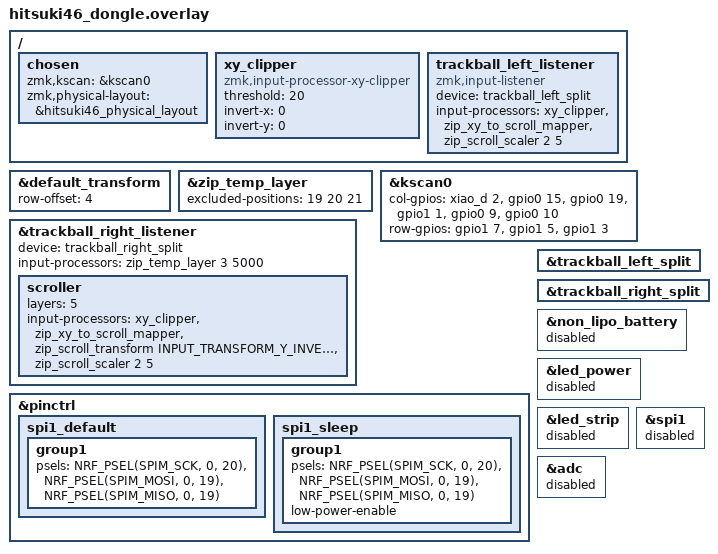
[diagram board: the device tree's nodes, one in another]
#include "hitsuki46.dtsi"
#include <dt-bindings/zmk/input_transform.h>
#include <dt-bindings/input/input-event-codes.h>
#include <input/processors.dtsi>
#include <dt-bindings/zmk/pointing.h>

//=============================================================================
// Trackball Mode Configuration on the Prospector central dongle
// 0 = CURSOR mode (mouse cursor movement)
// 1 = SCROLL mode (scroll operation)
//=============================================================================
#define LEFT_TRACKBALL_MODE  1
#define RIGHT_TRACKBALL_MODE 0
//=============================================================================

/ {
    chosen {
        zmk,kscan = &kscan0;
        zmk,physical-layout = &hitsuki46_physical_layout;
        /* The dongle has no local battery sensor (non_lipo_battery and adc are
         * disabled below). Drop the zmk,battery chosen inherited from the dtsi so
         * battery.c does not try to DEVICE_DT_GET a disabled device. Peripheral
         * battery levels are still fetched/reported via the split central. */
        /delete-property/ zmk,battery;
    };

    xy_clipper: xy_clipper {
        compatible = "zmk,input-processor-xy-clipper";
        #input-processor-cells = <0>;
        threshold = <20>;
        invert-x = <0>;
        invert-y = <0>;
    };

    // Left trackball input forwarded from the L peripheral.
    trackball_left_listener: trackball_left_listener {
        compatible = "zmk,input-listener";
        status = "okay";
        device = <&trackball_left_split>;

#if LEFT_TRACKBALL_MODE == 1
        input-processors =
            <&xy_clipper>,
            <&zip_xy_to_scroll_mapper>,
            <&zip_scroll_scaler 2 5>;
#else
        input-processors =
            <&zip_xy_transform INPUT_TRANSFORM_Y_INVERT>,
            <&zip_temp_layer 3 5000>;

        scroller {
            layers = <5>;
            input-processors =
                <&xy_clipper>,
                <&zip_xy_to_scroll_mapper>,
                <&zip_scroll_scaler 2 5>;
        };
#endif
    };
};

&default_transform {
    row-offset = <4>;
};

// Keep the auto mouse layer active only while pressing J/K/L.
&zip_temp_layer {
    excluded-positions = <19 20 21>;
};

// Right trackball input forwarded from the R peripheral.
&trackball_right_listener {
    status = "okay";
    device = <&trackball_right_split>;

#if RIGHT_TRACKBALL_MODE == 1
    input-processors =
        <&xy_clipper>,
        <&zip_xy_to_scroll_mapper>,
        <&zip_scroll_transform INPUT_TRANSFORM_Y_INVERT>,
        <&zip_scroll_scaler 2 5>;
#else
    input-processors = <&zip_temp_layer 3 5000>;

    scroller {
        layers = <5>;
        input-processors =
            <&xy_clipper>,
            <&zip_xy_to_scroll_mapper>,
            <&zip_scroll_transform INPUT_TRANSFORM_Y_INVERT>,
            <&zip_scroll_scaler 2 5>;
    };
#endif
};



/* Dongle local 3x6 matrix. diode-direction col2row (from hitsuki46.dtsi):
 *   columns are driven (outputs), rows are read (inputs, pull-down).
 * Extend the kscan0 node defined in hitsuki46.dtsi with the dongle's own pins.
 * row-gpios is overridden to the dongle's 3 rows (dtsi default is 4 rows). */
&kscan0 {
    col-gpios
        = <&xiao_d  2 GPIO_ACTIVE_HIGH>   /* col0  D2    P0.28 */
        , <&gpio0  15 GPIO_ACTIVE_HIGH>   /* col1  P0.15       */
        , <&gpio0  19 GPIO_ACTIVE_HIGH>   /* col2  P0.19       */
        , <&gpio1   1 GPIO_ACTIVE_HIGH>   /* col3  P1.01       */
        , <&gpio0   9 GPIO_ACTIVE_HIGH>   /* col4  P0.09 (NFC1)*/
        , <&gpio0  10 GPIO_ACTIVE_HIGH>   /* col5  P0.10 (NFC2)*/
        ;

    row-gpios
        = <&gpio1   7 (GPIO_ACTIVE_HIGH | GPIO_PULL_DOWN)>  /* row0  P1.07 */
        , <&gpio1   5 (GPIO_ACTIVE_HIGH | GPIO_PULL_DOWN)>  /* row1  P1.05 */
        , <&gpio1   3 (GPIO_ACTIVE_HIGH | GPIO_PULL_DOWN)>  /* row2  P1.03 */
        ;
};

&pinctrl {
    spi1_default: spi1_default {
        group1 {
            psels = <NRF_PSEL(SPIM_SCK, 0, 20)>,
                <NRF_PSEL(SPIM_MOSI, 0, 19)>,
                <NRF_PSEL(SPIM_MISO, 0, 19)>;
        };
    };

    spi1_sleep: spi1_sleep {
        group1 {
            psels = <NRF_PSEL(SPIM_SCK, 0, 20)>,
                <NRF_PSEL(SPIM_MOSI, 0, 19)>,
                <NRF_PSEL(SPIM_MISO, 0, 19)>;
            low-power-enable;
        };
    };
};

// Receive split input streams on the central.
&trackball_left_split {};
&trackball_right_split {};

// The dongle does not have hitsuki46 hand-local battery/LED hardware.
&non_lipo_battery { status = "disabled"; };
&led_power { status = "disabled"; };
&led_strip { status = "disabled"; };
&spi1 { status = "disabled"; };
&adc { status = "disabled"; };
